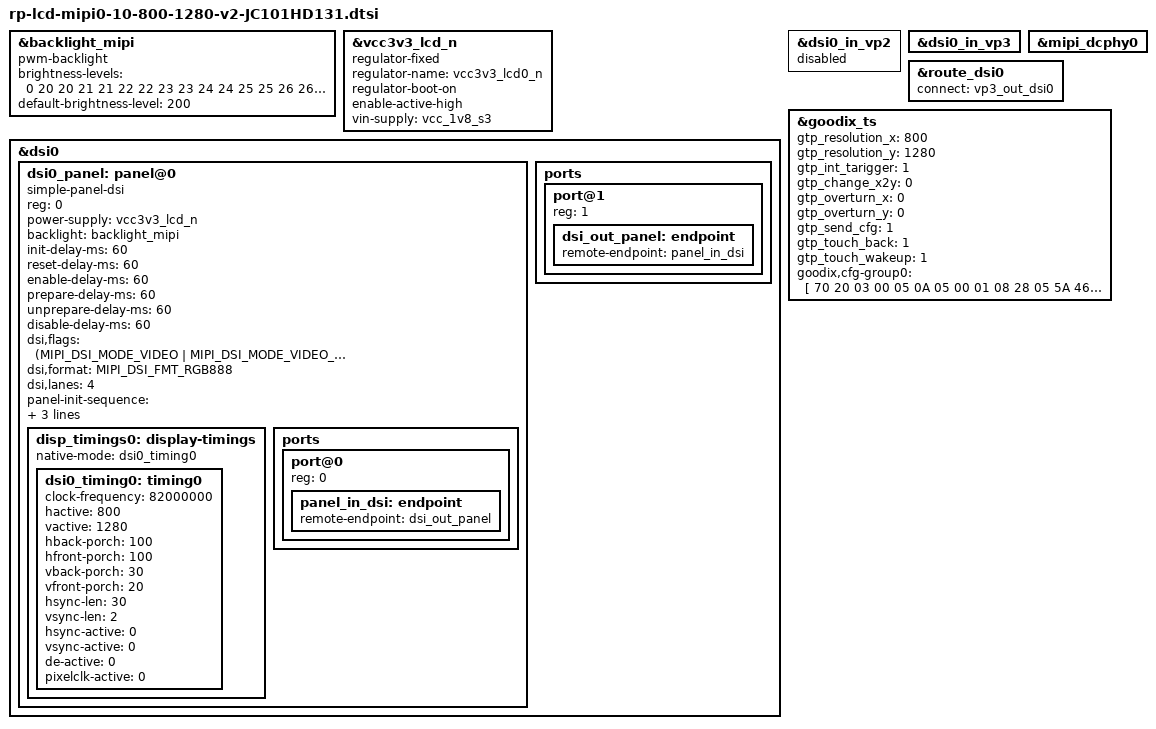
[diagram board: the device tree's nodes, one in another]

&backlight_mipi {
        compatible = "pwm-backlight";
        //pwms = <&pwm1 0 25000 0>;
        status = "okay";
        brightness-levels = <
              0  20  20  21  21  22  22  23
             23  24  24  25  25  26  26  27
             27  28  28  29  29  30  30  31
             31  32  32  33  33  34  34  35
             35  36  36  37  37  38  38  39
             40  41  42  43  44  45  46  47
             48  49  50  51  52  53  54  55
             56  57  58  59  60  61  62  63
             64  65  66  67  68  69  70  71
             72  73  74  75  76  77  78  79
             80  81  82  83  84  85  86  87
             88  89  90  91  92  93  94  95
             96  97  98  99 100 101 102 103
            104 105 106 107 108 109 110 111
            112 113 114 115 116 117 118 119
            120 121 122 123 124 125 126 127
            128 129 130 131 132 133 134 135
            136 137 138 139 140 141 142 143
            144 145 146 147 148 149 150 151
            152 153 154 155 156 157 158 159
            160 161 162 163 164 165 166 167
            168 169 170 171 172 173 174 175
            176 177 178 179 180 181 182 183
            184 185 186 187 188 189 190 191
            192 193 194 195 196 197 198 199
            200 201 202 203 204 205 206 207
            208 209 210 211 212 213 214 215
            216 217 218 219 220 221 222 223
            224 225 226 227 228 229 230 231
            232 233 234 235 236 237 238 239
            240 241 242 243 244 245 246 247
            248 249 250 251 252 253 254 255
        >;
        default-brightness-level = <200>;
    };


&vcc3v3_lcd_n {
  compatible = "regulator-fixed";
  regulator-name = "vcc3v3_lcd0_n";
  regulator-boot-on;
  enable-active-high;
  //gpio = <&gpio4 RK_PC2 GPIO_ACTIVE_HIGH>;
  vin-supply = <&vcc_1v8_s3>;
};





&dsi0 {
    status = "okay";
    //rockchip,lane-rate = <480000>;
    dsi0_panel: panel@0 {
        status = "okay";
        compatible = "simple-panel-dsi";
        reg = <0>;

        power-supply = <&vcc3v3_lcd_n>;

        //reset-gpios = <&gpio4 RK_PC6 GPIO_ACTIVE_LOW>;
        //pinctrl-names = "default";
        //pinctrl-0 = <&lcd_rst_gpio>;

        backlight = <&backlight_mipi>;
    init-delay-ms = <60>;
        reset-delay-ms = <60>;
        enable-delay-ms = <60>;
        prepare-delay-ms = <60>;
        unprepare-delay-ms = <60>;
        disable-delay-ms = <60>;
        dsi,flags = <(MIPI_DSI_MODE_VIDEO | MIPI_DSI_MODE_VIDEO_BURST |
            MIPI_DSI_MODE_LPM | MIPI_DSI_MODE_EOT_PACKET)>;
        dsi,format = <MIPI_DSI_FMT_RGB888>;
        dsi,lanes  = <4>;
        
        panel-init-sequence = [
                        05 78 01 11    //sleep out
                        05 20 01 29    //display on
        ];
        
        panel-exit-sequence = [
            05 78 01 28
            05 78 01 10
        ];

        disp_timings0: display-timings {
            native-mode = <&dsi0_timing0>;
            dsi0_timing0: timing0 {
                clock-frequency = <82000000>;
                hactive = <800>;
                vactive = <1280>;
                hback-porch = <100>;
                hfront-porch = <100>;
                vback-porch = <30>;
                vfront-porch = <20>;
                hsync-len = <30>;
                vsync-len = <2>;
                hsync-active = <0>;
                vsync-active = <0>;
                de-active = <0>;
                pixelclk-active = <0>;
            };
        };

        ports {
            #address-cells = <1>;
            #size-cells = <0>;

            port@0 {
                reg = <0>;
                panel_in_dsi: endpoint {
                    remote-endpoint = <&dsi_out_panel>;
                };
            };
        };
    };

    ports {
        #address-cells = <1>;
        #size-cells = <0>;

        port@1 {
            reg = <1>;
            dsi_out_panel: endpoint {
                remote-endpoint = <&panel_in_dsi>;
            };
        };
    };

};


&dsi0_in_vp2 {
    status = "disabled";
};

&dsi0_in_vp3 {
    status = "okay";
};

&mipi_dcphy0 {
    status = "okay";
};

&route_dsi0 {
    status = "okay";
    connect = <&vp3_out_dsi0>;
};


&goodix_ts {

        gtp_resolution_x = <800>;
        gtp_resolution_y = <1280>;
        gtp_int_tarigger = <1>;
        gtp_change_x2y = <0>;
        gtp_overturn_x = <0>;
        gtp_overturn_y = <0>;
        gtp_send_cfg = <1>;
        gtp_touch_back = <1>;
        gtp_touch_wakeup = <1>;

    goodix,cfg-group0 = [
        70 20 03 00 05 0A 05 00 01 08
        28 05 5A 46 03 05 00 00 00 00
        00 00 00 17 19 1B 14 8E 2E 99
        37 39 D3 07 00 00 00 80 02 2D
        00 00 00 00 00 00 00 00 00 00
        00 28 78 94 C5 02 07 00 00 04
        9A 2C 00 80 37 00 6B 45 00 5C
        56 00 50 6C 00 50 00 00 00 00
        00 00 00 00 00 00 00 00 00 00
        00 00 00 00 00 00 00 00 00 00
        00 00 00 00 00 00 00 00 00 00
        00 00 17 16 15 14 11 10 0F 0E
        0D 0C 09 08 07 06 05 04 01 00
        FF FF 00 00 00 00 00 00 00 00
        00 00 00 02 04 06 07 08 0A 0C
        0D 0F 10 11 12 28 27 26 25 24
        23 22 21 20 1F 1E 1C 1B 19 13
        FF FF FF FF 00 00 00 00 00 00
        00 00 00 00 AA 01
        ];
};
